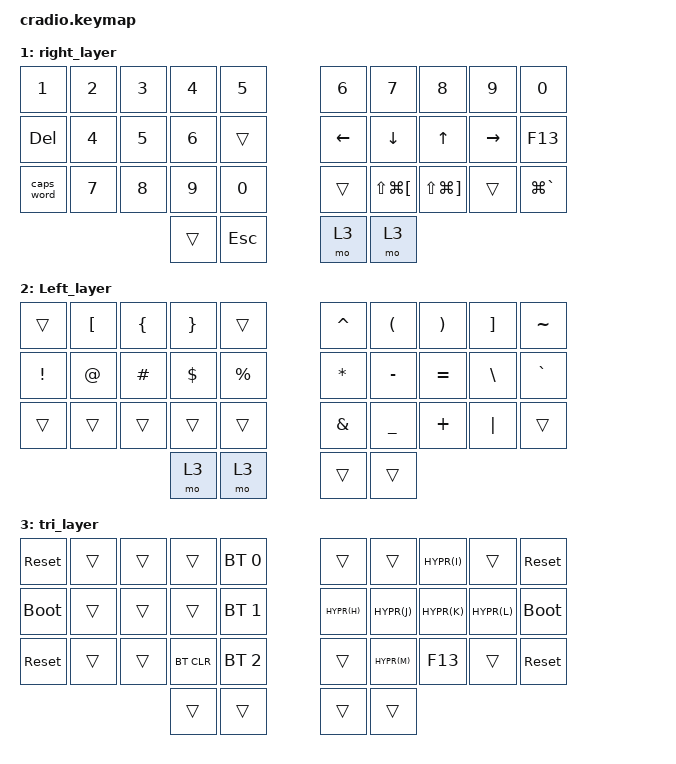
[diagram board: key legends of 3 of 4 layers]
// Copyright (c) 2022 The ZMK Contributors
// SPDX-License-Identifier: MIT

#include <behaviors.dtsi>
#include <dt-bindings/zmk/keys.h>
#include <dt-bindings/zmk/bt.h>

// Home row mods macro
#define HRML(k1,k2,k3,k4) &ht LCTRL k1  &ht LALT k2  &ht LSHFT k3  &ht LGUI k4
#define HRMR(k1,k2,k3,k4) &ht RGUI k1  &ht RSHFT k2  &ht RALT k3  &ht RCTRL k4
#define ZSHFT &ht LSHFT Z
#define SLSHFT &ht LSHFT FSLH

#define BR_PRV &kp LS(LG(LBKT))
#define BR_NXT &kp LS(LG(RBKT))

// Macos window iteration
#define WIN_NXT &kp LG(GRAVE)

#define HYPR(k1) &kp LG(LA(LC(LS(k1))))

/ {
    behaviors {
        ht: hold_tap {
            compatible = "zmk,behavior-hold-tap";
            #binding-cells = <2>;
            flavor = "tap-preferred";
            tapping-term-ms = <220>;
            quick-tap-ms = <150>;
            require-prior-idle-ms = <100>;
            bindings = <&kp>, <&kp>;
        };
    };

    /*
    conditional_layers {
        compatible = "zmk,conditional-layers";
        tri_layer {
            if-layers = <1 2>;
            then-layer = <3>;
        };
    };
    */

    keymap {
        compatible = "zmk,keymap";
        default_layer {
            bindings = <
        //╭──────────┬──────────┬──────────┬──────────┬──────────╮   ╭──────────┬──────────┬──────────┬──────────┬──────────╮
        //│  Q       │  W       │  E       │  R       │  T       │   │  Y       │  U       │  I       │  O       │  P       │
            &kp Q      &kp W      &kp E      &kp R      &kp T          &kp Y      &kp U      &kp I      &kp O      &kp P
        //├──────────┼──────────┼──────────┼──────────┼──────────┤   ├──────────┼──────────┼──────────┼──────────┼──────────┤
        //│  A       │  S       │  D       │  F       │  G       │   │  H       │  J       │  K       │  L       │ ' "      │
            HRML(A,        S,         D,         F)     &kp G          &kp H      HRMR(J,        K,         L,        SQT)
        //├──────────┼──────────┼──────────┼──────────┼──────────┤   ├──────────┼──────────┼──────────┼──────────┼──────────┤
        //│  Z       │  X       │  C       │  V       │  B       │   │  N       │  M       │ , <      │ . >      │ / ?      │
            ZSHFT      &kp X      &kp C      &kp V      &kp B          &kp N      &kp M      &kp COMMA  &kp DOT    SLSHFT
        //╰──────────┴──────────┴──────────┼──────────┼──────────┤   ├──────────┼──────────┼──────────┴──────────┴──────────╯
                                             &kp BSPC   &lt 2 TAB      &lt 3 ENTER &lt 1 SPACE 
        //                                 ╰──────────┴──────────╯   ╰──────────┴──────────╯
            >;
        };

        right_layer {
            bindings = <
        //╭──────────┬──────────┬──────────┬──────────┬──────────╮   ╭──────────┬──────────┬──────────┬──────────┬──────────╮
        //│ INSERT   │  1       │  2       │  3       │          │   │ HOME     │ PAGE DN  │ PAGE UP  │ END      │  :       │
            &kp N1     &kp N2     &kp N3     &kp N4     &kp N5         &kp N6     &kp N7     &kp N8     &kp N9     &kp N0
        //├──────────┼──────────┼──────────┼──────────┼──────────┤   ├──────────┼──────────┼──────────┼──────────┼──────────┤
        //│ DELETE   │  4       │  5       │  6       │          │   │ LEFT     │ DOWN     │ UP       │ RIGHT    │  F13     │
            &kp DEL    &kp N4     &kp N5     &kp N6     &trans         &kp LEFT   &kp DOWN   &kp UP     &kp RIGHT   &kp F13
        //├──────────┼──────────┼──────────┼──────────┼──────────┤   ├──────────┼──────────┼──────────┼──────────┼──────────┤
        //│ CAPS     │  7       │  8       │  9       │  0       │   │          │          │          │          │          │
           &caps_word  &kp N7     &kp N8     &kp N9     &kp N0         &trans     BR_PRV     BR_NXT     &trans     WIN_NXT
        //╰──────────┴──────────┴──────────┼──────────┼──────────┤   ├──────────┼──────────┼──────────┴──────────┴──────────╯
                                             &trans     &kp ESC        &mo 3     &mo 3
        //                                 ╰──────────┴──────────╯   ╰──────────┴──────────╯
            >;
        };

        Left_layer {
            bindings = <
        //╭──────────┬──────────┬──────────┬──────────┬──────────╮   ╭──────────┬──────────┬──────────┬──────────┬──────────╮
        //│          │  [       │  {       │  }       │          │   │  ^       │  (       │  )       │  ]       │  ~       │
            &trans     &kp LBKT   &kp LBRC   &kp RBRC   &trans         &kp CARET  &kp LPAR   &kp RPAR   &kp RBKT   &kp TILDE
        //├──────────┼──────────┼──────────┼──────────┼──────────┤   ├──────────┼──────────┼──────────┼──────────┼──────────┤
        //│  !       │  @       │  #       │  $       │  %       │   │  *       │  -       │  =       │  \       │  `       │
            &kp EXCL   &kp AT     &kp HASH   &kp DLLR   &kp PRCNT      &kp ASTRK  &kp MINUS  &kp EQUAL  &kp BSLH   &kp GRAVE
        //├──────────┼──────────┼──────────┼──────────┼──────────┤   ├──────────┼──────────┼──────────┼──────────┼──────────┤
        //│          │          │          │          │          │   │  &       │  _       │  +       │  │       │          │
            &trans     &trans     &trans     &trans     &trans         &kp AMPS   &kp UNDER  &kp PLUS   &kp PIPE   &trans
        //╰──────────┴──────────┴──────────┼──────────┼──────────┤   ├──────────┼──────────┼──────────┴──────────┴──────────╯
                                             &mo 3      &mo 3         &trans     &trans
        //                                 ╰──────────┴──────────╯   ╰──────────┴──────────╯
            >;
        };

        tri_layer {
            bindings = <
        //╭──────────┬──────────┬──────────┬──────────┬──────────╮   ╭──────────┬──────────┬──────────┬──────────┬──────────╮
        //│ RESET    │          │          │          │PROFILE 0 │   │          │          │          │          │  RESET   │
           &sys_reset  &trans     &trans     &trans    &bt BT_SEL 0    &trans     &trans     HYPR(I)    &trans    &sys_reset
        //├──────────┼──────────┼──────────┼──────────┼──────────┤   ├──────────┼──────────┼──────────┼──────────┼──────────┤
        //│BOOTLOADER│          │          │          │PROFILE 1 │   │          │          │          │          │BOOTLOADER│
          &bootloader  &trans     &trans     &trans    &bt BT_SEL 1    HYPR(H)    HYPR(J)    HYPR(K)    HYPR(L)    &bootloader
        //├──────────┼──────────┼──────────┼──────────┼──────────┤   ├──────────┼──────────┼──────────┼──────────┼──────────┤
        //│          │          │          │ CLEAR BT │PROFILE 2 │   │          │          │          │          │          │
            &sys_reset &trans     &trans    &bt BT_CLR &bt BT_SEL 2    &trans     HYPR(M)    &kp F13    &trans     &sys_reset
        //╰──────────┴──────────┴──────────┼──────────┼──────────┤   ├──────────┼──────────┼──────────┴──────────┴──────────╯
                                             &trans     &trans         &trans     &trans
        //                                 ╰──────────┴──────────╯   ╰──────────┴──────────╯
            >;
        };
    };
};
